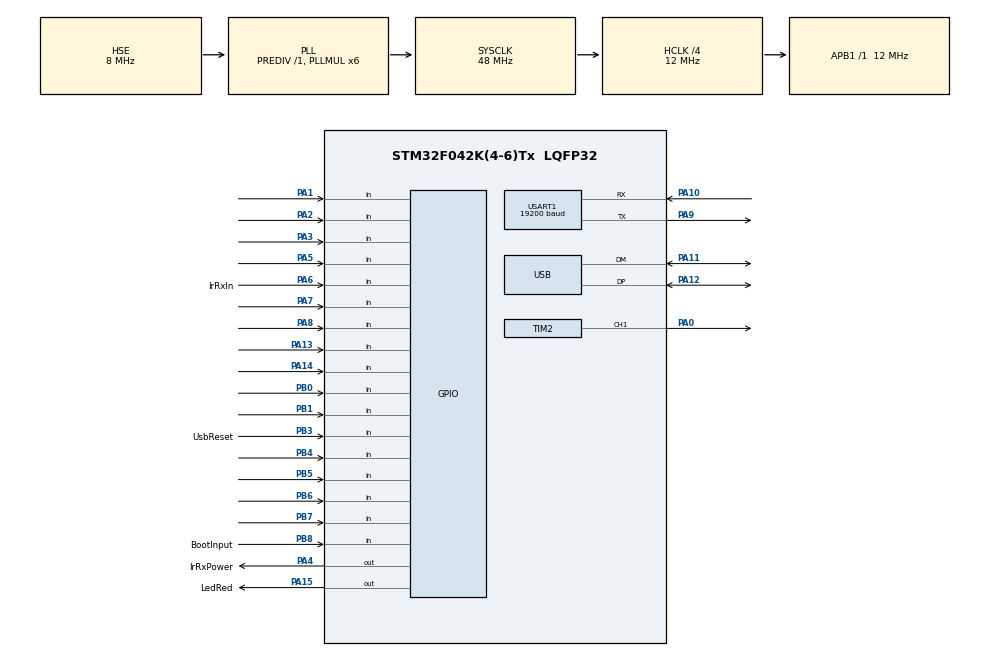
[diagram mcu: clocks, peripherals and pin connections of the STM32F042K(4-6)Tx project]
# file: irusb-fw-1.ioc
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Mcu.Family=STM32F0
TIM2.Channel-Output\ Compare1\ CH1=TIM_CHANNEL_1
PA2.GPIO_PuPd=GPIO_PULLDOWN
PA10.GPIO_PuPd=GPIO_PULLUP
USART1.BaudRate=19200
VP_IWDG_VS_IWDG.Mode=IWDG_Activate
PA3.GPIO_PuPd=GPIO_PULLDOWN
PA11.Mode=Device
PA6.GPIO_Label=IrRxIn
RCC.SYSCLKSource=RCC_SYSCLKSOURCE_PLLCLK
ProjectManager.StackSize=0x400
PA15.GPIO_Label=LedRed
PA12.Signal=USB_DP
PB1.GPIO_PuPd=GPIO_PULLDOWN
RCC.HCLKFreq_Value=12000000
TIM3.Period=600
PB6.Signal=GPIO_Input
PA1.GPIO_PuPd=GPIO_PULLDOWN
RCC.AHBFreq_Value=12000000
RCC.PLLMUL=RCC_PLL_MUL6
PA13.GPIO_PuPd=GPIO_PULLDOWN
PA6.GPIO_PuPd=GPIO_PULLUP
PB3.GPIO_PuPd=GPIO_PULLDOWN
USART1.OverrunDisableParam=ADVFEATURE_OVERRUN_DISABLE
PA5.GPIO_PuPd=GPIO_PULLDOWN
PB7.Signal=GPIO_Input
PA8.Signal=GPIO_Input
PA0.Signal=S_TIM2_CH1_ETR
Mcu.Package=LQFP32
PB1.Signal=GPIO_Input
PA6.Signal=GPIO_Input
IWDG.Reload=157
PA10.Signal=USART1_RX
PA15.Signal=GPIO_Output
USART1.DMADisableonRxErrorParam=ADVFEATURE_DMA_DISABLEONRXERROR
RCC.APB1TimFreq_Value=12000000
PF1-OSC_OUT.Mode=HSE-External-Oscillator
PA4.GPIO_Label=IrRxPower
RCC.USBClockSelection=RCC_USBCLKSOURCE_PLL
VP_TIM3_VS_ClockSourceINT.Mode=Internal
PF1-OSC_OUT.Signal=RCC_OSC_OUT
PB4.Signal=GPIO_Input
PA3.Signal=GPIO_Input
PB3.GPIO_Label=UsbReset
PB7.GPIO_PuPd=GPIO_PULLDOWN
PA10.Mode=Asynchronous
PB6.GPIO_PuPd=GPIO_PULLDOWN
USART1.VirtualMode-Asynchronous=VM_ASYNC
PA13.Signal=GPIO_Input
PB8.GPIO_Label=BootInput
PA9.Mode=Asynchronous
PA4.PinState=GPIO_PIN_SET
ProjectManager.TargetToolchain=Makefile
PA9.Signal=USART1_TX
PB4.GPIO_PuPd=GPIO_PULLDOWN
RCC.USBFreq_Value=48000000
PA7.GPIO_PuPd=GPIO_PULLDOWN
PA1.Signal=GPIO_Input
PF0-OSC_IN.Mode=HSE-External-Oscillator
PA5.Signal=GPIO_Input
board=custom
NVIC.TIM3_IRQn=true\:0\:0\:false\:false\:true\:true\:true
RCC.AHBCLKDivider=RCC_SYSCLK_DIV4
PA14.GPIO_PuPd=GPIO_PULLDOWN
Mcu.Name=STM32F042K(4-6)Tx
PA2.Signal=GPIO_Input
PB3.Signal=GPIO_Input
PA4.Signal=GPIO_Output
RCC.SYSCLKFreq_VALUE=48000000
PB5.Signal=GPIO_Input
PA12.Mode=Device
PB5.GPIO_PuPd=GPIO_PULLDOWN
PA11.Signal=USB_DM
SH.S_TIM2_CH1_ETR.0=TIM2_CH1,Output Compare1 CH1
PA14.Signal=GPIO_Input
ProjectManager.HeapSize=0x200
PA8.GPIO_PuPd=GPIO_PULLDOWN
IWDG.Prescaler=IWDG_PRESCALER_256
PB8.Signal=GPIO_Input
PF0-OSC_IN.Signal=RCC_OSC_IN
RCC.APB1Freq_Value=12000000
PB0.Signal=GPIO_Input
IWDG.Window=157
PB0.GPIO_PuPd=GPIO_PULLDOWN
PA7.Signal=GPIO_Input

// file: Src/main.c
/* USER CODE BEGIN Header */
/**
  ******************************************************************************
  * @file           : main.c
  * @brief          : Main program body
  ******************************************************************************
  * @attention
  *
  * <h2><center>&copy; Copyright (c) 2020 STMicroelectronics.
  * All rights reserved.</center></h2>
  *
  * This software component is licensed by ST under BSD 3-Clause license,
  * the "License"; You may not use this file except in compliance with the
  * License. You may obtain a copy of the License at:
  *                        opensource.org/licenses/BSD-3-Clause
  *
  ******************************************************************************
  */
/* USER CODE END Header */

#include "main.h"

/* USER CODE BEGIN Includes */

#include "irusb.h"

/* USER CODE END Includes */

IWDG_HandleTypeDef hiwdg;

TIM_HandleTypeDef htim2;
TIM_HandleTypeDef htim3;

UART_HandleTypeDef huart1;

void SystemClock_Config(void);
static void MX_GPIO_Init(void);
static void MX_USART1_UART_Init(void);
static void MX_TIM2_Init(void);
static void MX_IWDG_Init(void);
static void MX_TIM3_Init(void);

int main(void)
{

  /* MCU Configuration--------------------------------------------------------*/

  /* Reset of all peripherals, Initializes the Flash interface and the Systick. */
  HAL_Init();

  /* Configure the system clock */
  SystemClock_Config();

  /* Initialize all configured peripherals */
  MX_GPIO_Init();
  MX_IWDG_Init();
  MX_USART1_UART_Init();
  MX_TIM2_Init();
  MX_TIM3_Init();
  /* USER CODE BEGIN 2 */

  initIrusb();

  /* USER CODE END 2 */

  /* Infinite loop */
  /* USER CODE BEGIN WHILE */
  while (1)
  {
    loopIrusb();

    /* USER CODE END WHILE */

  }
}

void SystemClock_Config(void)
{
  RCC_OscInitTypeDef RCC_OscInitStruct = {0};
  RCC_ClkInitTypeDef RCC_ClkInitStruct = {0};
  RCC_PeriphCLKInitTypeDef PeriphClkInit = {0};

  /** Initializes the CPU, AHB and APB busses clocks
  */
  RCC_OscInitStruct.OscillatorType = RCC_OSCILLATORTYPE_LSI|RCC_OSCILLATORTYPE_HSE;
  RCC_OscInitStruct.HSEState = RCC_HSE_ON;
  RCC_OscInitStruct.LSIState = RCC_LSI_ON;
  RCC_OscInitStruct.PLL.PLLState = RCC_PLL_ON;
  RCC_OscInitStruct.PLL.PLLSource = RCC_PLLSOURCE_HSE;
  RCC_OscInitStruct.PLL.PLLMUL = RCC_PLL_MUL6;
  RCC_OscInitStruct.PLL.PREDIV = RCC_PREDIV_DIV1;
  if (HAL_RCC_OscConfig(&RCC_OscInitStruct) != HAL_OK)
  {
    Error_Handler();
  }
  /** Initializes the CPU, AHB and APB busses clocks
  */
  RCC_ClkInitStruct.ClockType = RCC_CLOCKTYPE_HCLK|RCC_CLOCKTYPE_SYSCLK
                              |RCC_CLOCKTYPE_PCLK1;
  RCC_ClkInitStruct.SYSCLKSource = RCC_SYSCLKSOURCE_PLLCLK;
  RCC_ClkInitStruct.AHBCLKDivider = RCC_SYSCLK_DIV4;
  RCC_ClkInitStruct.APB1CLKDivider = RCC_HCLK_DIV1;

  if (HAL_RCC_ClockConfig(&RCC_ClkInitStruct, FLASH_LATENCY_1) != HAL_OK)
  {
    Error_Handler();
  }
  PeriphClkInit.PeriphClockSelection = RCC_PERIPHCLK_USB|RCC_PERIPHCLK_USART1;
  PeriphClkInit.Usart1ClockSelection = RCC_USART1CLKSOURCE_PCLK1;
  PeriphClkInit.UsbClockSelection = RCC_USBCLKSOURCE_PLL;

  if (HAL_RCCEx_PeriphCLKConfig(&PeriphClkInit) != HAL_OK)
  {
    Error_Handler();
  }
}

static void MX_IWDG_Init(void)
{

  /* USER CODE BEGIN IWDG_Init 0 */

  /* Setting the prescaler fails for some reason if the program is started from
   the DFU bootloader. When starting from the DFU bootloader, the prescaler
   stays at the value 6 = divider 256. So in order to have a consistent
   behavior, we use this prescaler in every case. Luckily setting the reload
   value works. 40kHz/256 = 157. So one second until timeout.
   Since the clock can be even 50kHz according to the datasheet, a watchdog
   reset within 0.79s is required.
  */

  /* USER CODE END IWDG_Init 0 */

  hiwdg.Instance = IWDG;
  hiwdg.Init.Prescaler = IWDG_PRESCALER_256;
  hiwdg.Init.Window = 157;
  hiwdg.Init.Reload = 157;
  if (HAL_IWDG_Init(&hiwdg) != HAL_OK)
  {
    Error_Handler();
  }

}

static void MX_TIM2_Init(void)
{

  TIM_MasterConfigTypeDef sMasterConfig = {0};
  TIM_OC_InitTypeDef sConfigOC = {0};

  htim2.Instance = TIM2;
  htim2.Init.Prescaler = 0;
  htim2.Init.CounterMode = TIM_COUNTERMODE_UP;
  htim2.Init.Period = 0;
  htim2.Init.ClockDivision = TIM_CLOCKDIVISION_DIV1;
  htim2.Init.AutoReloadPreload = TIM_AUTORELOAD_PRELOAD_DISABLE;
  if (HAL_TIM_OC_Init(&htim2) != HAL_OK)
  {
    Error_Handler();
  }
  sMasterConfig.MasterOutputTrigger = TIM_TRGO_RESET;
  sMasterConfig.MasterSlaveMode = TIM_MASTERSLAVEMODE_DISABLE;
  if (HAL_TIMEx_MasterConfigSynchronization(&htim2, &sMasterConfig) != HAL_OK)
  {
    Error_Handler();
  }
  sConfigOC.OCMode = TIM_OCMODE_TIMING;
  sConfigOC.Pulse = 0;
  sConfigOC.OCPolarity = TIM_OCPOLARITY_HIGH;
  sConfigOC.OCFastMode = TIM_OCFAST_DISABLE;
  if (HAL_TIM_OC_ConfigChannel(&htim2, &sConfigOC, TIM_CHANNEL_1) != HAL_OK)
  {
    Error_Handler();
  }
  HAL_TIM_MspPostInit(&htim2);

}

static void MX_TIM3_Init(void)
{

  TIM_ClockConfigTypeDef sClockSourceConfig = {0};
  TIM_MasterConfigTypeDef sMasterConfig = {0};

  htim3.Instance = TIM3;
  htim3.Init.Prescaler = 0;
  htim3.Init.CounterMode = TIM_COUNTERMODE_UP;
  htim3.Init.Period = 600;
  htim3.Init.ClockDivision = TIM_CLOCKDIVISION_DIV1;
  htim3.Init.AutoReloadPreload = TIM_AUTORELOAD_PRELOAD_DISABLE;
  if (HAL_TIM_Base_Init(&htim3) != HAL_OK)
  {
    Error_Handler();
  }
  sClockSourceConfig.ClockSource = TIM_CLOCKSOURCE_INTERNAL;
  if (HAL_TIM_ConfigClockSource(&htim3, &sClockSourceConfig) != HAL_OK)
  {
    Error_Handler();
  }
  sMasterConfig.MasterOutputTrigger = TIM_TRGO_RESET;
  sMasterConfig.MasterSlaveMode = TIM_MASTERSLAVEMODE_DISABLE;
  if (HAL_TIMEx_MasterConfigSynchronization(&htim3, &sMasterConfig) != HAL_OK)
  {
    Error_Handler();
  }

}

static void MX_USART1_UART_Init(void)
{

  huart1.Instance = USART1;
  huart1.Init.BaudRate = 19200;
  huart1.Init.WordLength = UART_WORDLENGTH_8B;
  huart1.Init.StopBits = UART_STOPBITS_1;
  huart1.Init.Parity = UART_PARITY_NONE;
  huart1.Init.Mode = UART_MODE_TX_RX;
  huart1.Init.HwFlowCtl = UART_HWCONTROL_NONE;
  huart1.Init.OverSampling = UART_OVERSAMPLING_16;
  huart1.Init.OneBitSampling = UART_ONE_BIT_SAMPLE_DISABLE;
  huart1.AdvancedInit.AdvFeatureInit = UART_ADVFEATURE_RXOVERRUNDISABLE_INIT|UART_ADVFEATURE_DMADISABLEONERROR_INIT;
  huart1.AdvancedInit.OverrunDisable = UART_ADVFEATURE_OVERRUN_DISABLE;
  huart1.AdvancedInit.DMADisableonRxError = UART_ADVFEATURE_DMA_DISABLEONRXERROR;
  if (HAL_UART_Init(&huart1) != HAL_OK)
  {
    Error_Handler();
  }

}

static void MX_GPIO_Init(void)
{
  GPIO_InitTypeDef GPIO_InitStruct = {0};

  /* GPIO Ports Clock Enable */
  __HAL_RCC_GPIOF_CLK_ENABLE();
  __HAL_RCC_GPIOA_CLK_ENABLE();
  __HAL_RCC_GPIOB_CLK_ENABLE();

  /*Configure GPIO pin Output Level */
  HAL_GPIO_WritePin(IrRxPower_GPIO_Port, IrRxPower_Pin, GPIO_PIN_SET);

  /*Configure GPIO pin Output Level */
  HAL_GPIO_WritePin(LedRed_GPIO_Port, LedRed_Pin, GPIO_PIN_RESET);

  /*Configure GPIO pins : PA1 PA2 PA3 PA5
                           PA7 PA8 PA13 PA14 */
  GPIO_InitStruct.Pin = GPIO_PIN_1|GPIO_PIN_2|GPIO_PIN_3|GPIO_PIN_5
                          |GPIO_PIN_7|GPIO_PIN_8|GPIO_PIN_13|GPIO_PIN_14;
  GPIO_InitStruct.Mode = GPIO_MODE_INPUT;
  GPIO_InitStruct.Pull = GPIO_PULLDOWN;
  HAL_GPIO_Init(GPIOA, &GPIO_InitStruct);

  /*Configure GPIO pins : IrRxPower_Pin LedRed_Pin */
  GPIO_InitStruct.Pin = IrRxPower_Pin|LedRed_Pin;
  GPIO_InitStruct.Mode = GPIO_MODE_OUTPUT_PP;
  GPIO_InitStruct.Pull = GPIO_NOPULL;
  GPIO_InitStruct.Speed = GPIO_SPEED_FREQ_LOW;
  HAL_GPIO_Init(GPIOA, &GPIO_InitStruct);

  /*Configure GPIO pin : IrRxIn_Pin */
  GPIO_InitStruct.Pin = IrRxIn_Pin;
  GPIO_InitStruct.Mode = GPIO_MODE_INPUT;
  GPIO_InitStruct.Pull = GPIO_PULLUP;
  HAL_GPIO_Init(IrRxIn_GPIO_Port, &GPIO_InitStruct);

  /*Configure GPIO pins : PB0 PB1 PB4 PB5
                           PB6 PB7 */
  GPIO_InitStruct.Pin = GPIO_PIN_0|GPIO_PIN_1|GPIO_PIN_4|GPIO_PIN_5
                          |GPIO_PIN_6|GPIO_PIN_7;
  GPIO_InitStruct.Mode = GPIO_MODE_INPUT;
  GPIO_InitStruct.Pull = GPIO_PULLDOWN;
  HAL_GPIO_Init(GPIOB, &GPIO_InitStruct);

  /*Configure GPIO pin : UsbReset_Pin */
  GPIO_InitStruct.Pin = UsbReset_Pin;
  GPIO_InitStruct.Mode = GPIO_MODE_INPUT;
  /* If R7 is empty, there should be a pull up or pull down to prevent floating
     If R7 is present, it sould not alter the function of the internal pull-up
  */
  GPIO_InitStruct.Pull = GPIO_PULLDOWN;
  HAL_GPIO_Init(UsbReset_GPIO_Port, &GPIO_InitStruct);

}

void Error_Handler(void)
{
}

/************************ (C) COPYRIGHT STMicroelectronics *****END OF FILE****/
